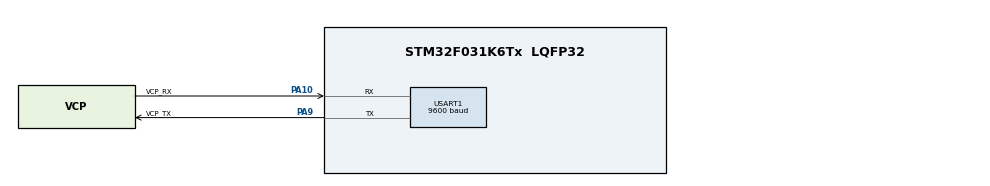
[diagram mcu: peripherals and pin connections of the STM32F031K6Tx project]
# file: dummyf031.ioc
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Mcu.Family=STM32F0
Mcu.Name=STM32F031K6Tx
Mcu.Package=LQFP32
NVIC.USART1_IRQn=true\:0\:0\:false\:false\:true\:true\:true\:true
PA10.GPIO_Label=VCP_RX
PA10.GPIO_ModeDefaultPP=GPIO_MODE_AF_PP
PA10.Mode=Asynchronous
PA10.Signal=USART1_RX
PA13.GPIO_Label=SWDIO
PA13.Mode=Serial_Wire
PA13.Signal=SYS_SWDIO
PA14.GPIO_Label=SWCLK
PA14.Mode=Serial_Wire
PA14.Signal=SYS_SWCLK
PA9.GPIO_Label=VCP_TX
PA9.GPIO_ModeDefaultPP=GPIO_MODE_AF_PP
PA9.Mode=Asynchronous
PA9.Signal=USART1_TX
PF0-OSC_IN.Mode=HSE-External-Clock-Source
PF0-OSC_IN.Signal=RCC_OSC_IN
ProjectManager.HeapSize=0x200
ProjectManager.StackSize=0x400
ProjectManager.TargetToolchain=STM32CubeIDE
USART1.BaudRate=9600
USART1.VirtualMode-Asynchronous=VM_ASYNC
board=NUCLEO-F031K6

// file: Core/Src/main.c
/* USER CODE BEGIN Header */
/**
  ******************************************************************************
  * @file           : main.c
  * @brief          : Main program body
  ******************************************************************************
  * @attention
  *
  * Copyright (c) 2022 STMicroelectronics.
  * All rights reserved.
  *
  * This software is licensed under terms that can be found in the LICENSE file
  * in the root directory of this software component.
  * If no LICENSE file comes with this software, it is provided AS-IS.
  *
  ******************************************************************************
  */
/* USER CODE END Header */
#include "main.h"

 UART_HandleTypeDef huart1;

void SystemClock_Config(void);
static void MX_GPIO_Init(void);
static void MX_USART1_UART_Init(void);

/* USER CODE BEGIN 0 */
char dummymsg[]={
		 "dummymessage \n\r"
 };

uint8_t rxdata[10] = {0};
/* USER CODE END 0 */

int main(void)
{

  /* MCU Configuration--------------------------------------------------------*/

  /* Reset of all peripherals, Initializes the Flash interface and the Systick. */
  HAL_Init();

  /* Configure the system clock */
  SystemClock_Config();

  /* Initialize all configured peripherals */
  MX_GPIO_Init();
  MX_USART1_UART_Init();

  /* Infinite loop */
  while (1)
  {

    /* USER CODE BEGIN 3 */
//	  HAL_UART_Receive_IT(&huart1, rxdata, 10);
//	  HAL_GPIO_WritePin(LED2_GPIO_Port, LED2_Pin, GPIO_PIN_SET);
	  for (int i=0; i<17; i++){
	  HAL_UART_Transmit(&huart1, &dummymsg[i], 1, 1000);
	  };
//	  HAL_GPIO_WritePin(LED2_GPIO_Port, LED2_Pin, GPIO_PIN_RESET);
  }
  /* USER CODE END 3 */
}

void SystemClock_Config(void)
{
  RCC_OscInitTypeDef RCC_OscInitStruct = {0};
  RCC_ClkInitTypeDef RCC_ClkInitStruct = {0};
  RCC_PeriphCLKInitTypeDef PeriphClkInit = {0};

  /** Initializes the RCC Oscillators according to the specified parameters
  * in the RCC_OscInitTypeDef structure.
  */
  RCC_OscInitStruct.OscillatorType = RCC_OSCILLATORTYPE_HSI;
  RCC_OscInitStruct.HSIState = RCC_HSI_ON;
  RCC_OscInitStruct.HSICalibrationValue = RCC_HSICALIBRATION_DEFAULT;
  RCC_OscInitStruct.PLL.PLLState = RCC_PLL_NONE;
  if (HAL_RCC_OscConfig(&RCC_OscInitStruct) != HAL_OK)
  {
    Error_Handler();
  }

  /** Initializes the CPU, AHB and APB buses clocks
  */
  RCC_ClkInitStruct.ClockType = RCC_CLOCKTYPE_HCLK|RCC_CLOCKTYPE_SYSCLK
                              |RCC_CLOCKTYPE_PCLK1;
  RCC_ClkInitStruct.SYSCLKSource = RCC_SYSCLKSOURCE_HSI;
  RCC_ClkInitStruct.AHBCLKDivider = RCC_SYSCLK_DIV1;
  RCC_ClkInitStruct.APB1CLKDivider = RCC_HCLK_DIV1;

  if (HAL_RCC_ClockConfig(&RCC_ClkInitStruct, FLASH_LATENCY_0) != HAL_OK)
  {
    Error_Handler();
  }
  PeriphClkInit.PeriphClockSelection = RCC_PERIPHCLK_USART1;
  PeriphClkInit.Usart1ClockSelection = RCC_USART1CLKSOURCE_PCLK1;
  if (HAL_RCCEx_PeriphCLKConfig(&PeriphClkInit) != HAL_OK)
  {
    Error_Handler();
  }
}

static void MX_USART1_UART_Init(void)
{

  huart1.Instance = USART1;
  huart1.Init.BaudRate = 9600;
  huart1.Init.WordLength = UART_WORDLENGTH_8B;
  huart1.Init.StopBits = UART_STOPBITS_1;
  huart1.Init.Parity = UART_PARITY_NONE;
  huart1.Init.Mode = UART_MODE_TX_RX;
  huart1.Init.HwFlowCtl = UART_HWCONTROL_NONE;
  huart1.Init.OverSampling = UART_OVERSAMPLING_16;
  huart1.Init.OneBitSampling = UART_ONE_BIT_SAMPLE_DISABLE;
  huart1.AdvancedInit.AdvFeatureInit = UART_ADVFEATURE_NO_INIT;
  if (HAL_UART_Init(&huart1) != HAL_OK)
  {
    Error_Handler();
  }

}

static void MX_GPIO_Init(void)
{

  /* GPIO Ports Clock Enable */
  __HAL_RCC_GPIOF_CLK_ENABLE();
  __HAL_RCC_GPIOA_CLK_ENABLE();

}

void Error_Handler(void)
{
  __disable_irq();
  while (1)
  {
  }
}
